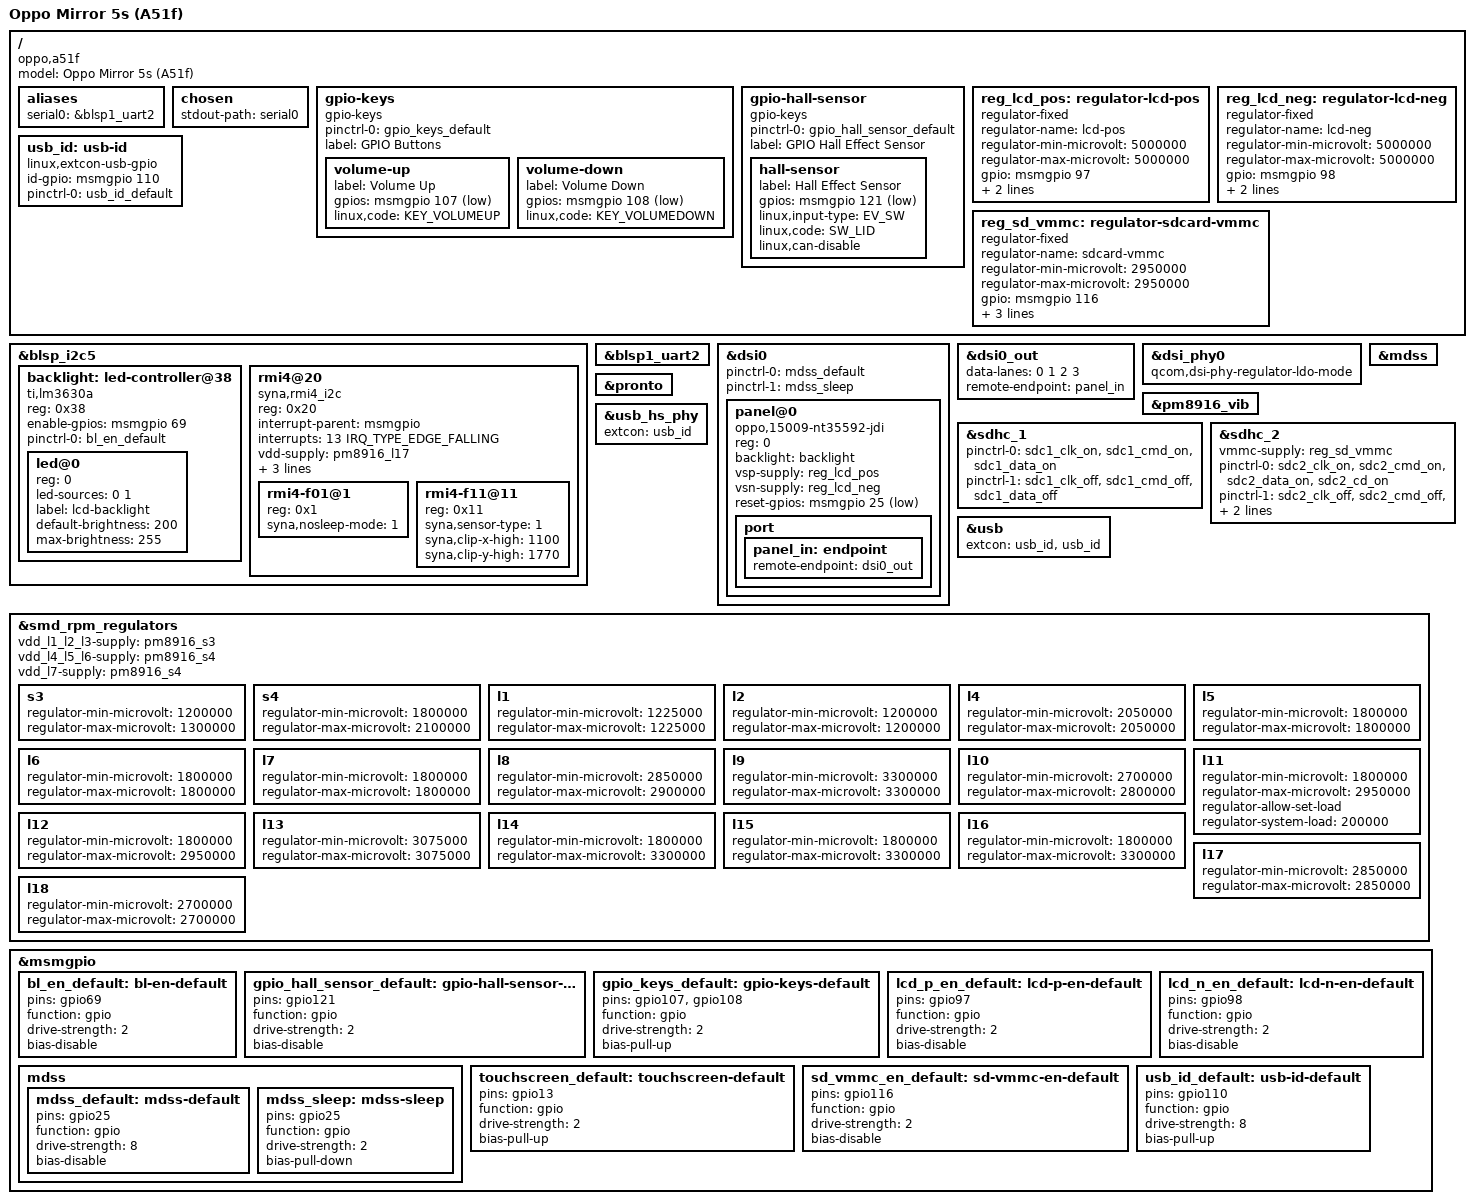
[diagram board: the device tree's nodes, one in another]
// SPDX-License-Identifier: GPL-2.0-only

/dts-v1/;

#include "msm8916-pm8916.dtsi"
#include "arm/qcom-msm8916-no-psci.dtsi"
#include <dt-bindings/gpio/gpio.h>

/ {
	model = "Oppo Mirror 5s (A51f)";
	compatible = "oppo,a51f", "qcom,msm8916";

	aliases {
		serial0 = &blsp1_uart2;
	};

	chosen {
		stdout-path = "serial0";
	};

	gpio-keys {
		compatible = "gpio-keys";

		pinctrl-names = "default";
		pinctrl-0 = <&gpio_keys_default>;

		label = "GPIO Buttons";

		volume-up {
			label = "Volume Up";
			gpios = <&msmgpio 107 GPIO_ACTIVE_LOW>;
			linux,code = <KEY_VOLUMEUP>;
		};

		volume-down {
			label = "Volume Down";
			gpios = <&msmgpio 108 GPIO_ACTIVE_LOW>;
			linux,code = <KEY_VOLUMEDOWN>;
		};
	};

	gpio-hall-sensor {
		compatible = "gpio-keys";

		pinctrl-names = "default";
		pinctrl-0 = <&gpio_hall_sensor_default>;

		label = "GPIO Hall Effect Sensor";

		hall-sensor {
			label = "Hall Effect Sensor";
			gpios = <&msmgpio 121 GPIO_ACTIVE_LOW>;
			linux,input-type = <EV_SW>;
			linux,code = <SW_LID>;
			linux,can-disable;
		};
	};

	reg_lcd_pos: regulator-lcd-pos {
		compatible = "regulator-fixed";
		regulator-name = "lcd-pos";
		regulator-min-microvolt = <5000000>;
		regulator-max-microvolt = <5000000>;
		gpio = <&msmgpio 97 GPIO_ACTIVE_HIGH>;
		enable-active-high;
		pinctrl-names = "default";
		pinctrl-0 = <&lcd_p_en_default>;
	};

	reg_lcd_neg: regulator-lcd-neg {
		compatible = "regulator-fixed";
		regulator-name = "lcd-neg";
		regulator-min-microvolt = <5000000>;
		regulator-max-microvolt = <5000000>;
		gpio = <&msmgpio 98 GPIO_ACTIVE_HIGH>;
		enable-active-high;
		pinctrl-names = "default";
		pinctrl-0 = <&lcd_n_en_default>;
	};

	reg_sd_vmmc: regulator-sdcard-vmmc {
		compatible = "regulator-fixed";
		regulator-name = "sdcard-vmmc";
		regulator-min-microvolt = <2950000>;
		regulator-max-microvolt = <2950000>;

		gpio = <&msmgpio 116 GPIO_ACTIVE_HIGH>;
		enable-active-high;

		startup-delay-us = <200>;

		pinctrl-names = "default";
		pinctrl-0 = <&sd_vmmc_en_default>;
	};

	usb_id: usb-id {
		compatible = "linux,extcon-usb-gpio";
		id-gpio = <&msmgpio 110 GPIO_ACTIVE_HIGH>;
		pinctrl-names = "default";
		pinctrl-0 = <&usb_id_default>;
	};
};

&blsp_i2c5 {
	status = "okay";

	backlight: led-controller@38 {
		compatible = "ti,lm3630a";
		reg = <0x38>;
		enable-gpios = <&msmgpio 69 GPIO_ACTIVE_HIGH>;
		pinctrl-names = "default";
		pinctrl-0 = <&bl_en_default>;
		#address-cells = <1>;
		#size-cells = <0>;

		led@0 {
			reg = <0>;
			led-sources = <0 1>;
			label = "lcd-backlight";
			default-brightness = <200>;
			max-brightness = <255>;
		};
	};

	rmi4@20 {
		compatible = "syna,rmi4_i2c";
		reg = <0x20>;
		#address-cells = <1>;
		#size-cells = <0>;

		interrupt-parent = <&msmgpio>;
		interrupts = <13 IRQ_TYPE_EDGE_FALLING>;

		vdd-supply = <&pm8916_l17>;
		vio-supply = <&pm8916_l6>;

		pinctrl-names = "default";
		pinctrl-0 = <&touchscreen_default>;

		syna,startup-delay-ms = <10>;

		rmi4-f01@1 {
			reg = <0x1>;
			syna,nosleep-mode = <1>; // Allow sleeping
		};

		rmi4-f11@11 {
			reg = <0x11>;
			syna,sensor-type = <1>; // Touchscreen
			syna,clip-x-high = <1100>;
			syna,clip-y-high = <1770>;
		};
	};
};

&blsp1_uart2 {
	status = "okay";
};

&dsi0 {
	pinctrl-names = "default", "sleep";
	pinctrl-0 = <&mdss_default>;
	pinctrl-1 = <&mdss_sleep>;

	panel@0 {
		compatible = "oppo,15009-nt35592-jdi";
		reg = <0>;

		backlight = <&backlight>;
		vsp-supply = <&reg_lcd_pos>;
		vsn-supply = <&reg_lcd_neg>;
		reset-gpios = <&msmgpio 25 GPIO_ACTIVE_LOW>;

		port {
			panel_in: endpoint {
				remote-endpoint = <&dsi0_out>;
			};
		};
	};
};

&dsi0_out {
	data-lanes = <0 1 2 3>;
	remote-endpoint = <&panel_in>;
};

&dsi_phy0 {
	qcom,dsi-phy-regulator-ldo-mode;
};

&mdss {
	status = "okay";
};

&pm8916_vib {
	status = "okay";
};

&pronto {
	status = "okay";
};

&sdhc_1 {
	status = "okay";

	pinctrl-names = "default", "sleep";
	pinctrl-0 = <&sdc1_clk_on &sdc1_cmd_on &sdc1_data_on>;
	pinctrl-1 = <&sdc1_clk_off &sdc1_cmd_off &sdc1_data_off>;
};

&sdhc_2 {
	status = "okay";
	vmmc-supply = <&reg_sd_vmmc>;

	pinctrl-names = "default", "sleep";
	pinctrl-0 = <&sdc2_clk_on &sdc2_cmd_on &sdc2_data_on &sdc2_cd_on>;
	pinctrl-1 = <&sdc2_clk_off &sdc2_cmd_off &sdc2_data_off &sdc2_cd_off>;

	cd-gpios = <&msmgpio 38 GPIO_ACTIVE_HIGH>;
};

&usb {
	status = "okay";
	extcon = <&usb_id>, <&usb_id>;
};

&usb_hs_phy {
	extcon = <&usb_id>;
};

&smd_rpm_regulators {
	vdd_l1_l2_l3-supply = <&pm8916_s3>;
	vdd_l4_l5_l6-supply = <&pm8916_s4>;
	vdd_l7-supply = <&pm8916_s4>;

	s3 {
		regulator-min-microvolt = <1200000>;
		regulator-max-microvolt = <1300000>;
	};

	s4 {
		regulator-min-microvolt = <1800000>;
		regulator-max-microvolt = <2100000>;
	};

	l1 {
		regulator-min-microvolt = <1225000>;
		regulator-max-microvolt = <1225000>;
	};

	l2 {
		regulator-min-microvolt = <1200000>;
		regulator-max-microvolt = <1200000>;
	};

	l4 {
		regulator-min-microvolt = <2050000>;
		regulator-max-microvolt = <2050000>;
	};

	l5 {
		regulator-min-microvolt = <1800000>;
		regulator-max-microvolt = <1800000>;
	};

	l6 {
		regulator-min-microvolt = <1800000>;
		regulator-max-microvolt = <1800000>;
	};

	l7 {
		regulator-min-microvolt = <1800000>;
		regulator-max-microvolt = <1800000>;
	};

	l8 {
		regulator-min-microvolt = <2850000>;
		regulator-max-microvolt = <2900000>;
	};

	l9 {
		regulator-min-microvolt = <3300000>;
		regulator-max-microvolt = <3300000>;
	};

	l10 {
		regulator-min-microvolt = <2700000>;
		regulator-max-microvolt = <2800000>;
	};

	l11 {
		regulator-min-microvolt = <1800000>;
		regulator-max-microvolt = <2950000>;
		regulator-allow-set-load;
		regulator-system-load = <200000>;
	};

	l12 {
		regulator-min-microvolt = <1800000>;
		regulator-max-microvolt = <2950000>;
	};

	l13 {
		regulator-min-microvolt = <3075000>;
		regulator-max-microvolt = <3075000>;
	};

	l14 {
		regulator-min-microvolt = <1800000>;
		regulator-max-microvolt = <3300000>;
	};

	l15 {
		regulator-min-microvolt = <1800000>;
		regulator-max-microvolt = <3300000>;
	};

	l16 {
		regulator-min-microvolt = <1800000>;
		regulator-max-microvolt = <3300000>;
	};

	l17 {
		regulator-min-microvolt = <2850000>;
		regulator-max-microvolt = <2850000>;
	};

	l18 {
		regulator-min-microvolt = <2700000>;
		regulator-max-microvolt = <2700000>;
	};
};

&msmgpio {
	bl_en_default: bl-en-default {
		pins = "gpio69";
		function = "gpio";

		drive-strength = <2>;
		bias-disable;
	};

	gpio_hall_sensor_default: gpio-hall-sensor-default {
		pins = "gpio121";
		function = "gpio";

		drive-strength = <2>;
		bias-disable;
	};

	gpio_keys_default: gpio-keys-default {
		pins = "gpio107", "gpio108";
		function = "gpio";

		drive-strength = <2>;
		bias-pull-up;
	};

	lcd_p_en_default: lcd-p-en-default {
		pins = "gpio97";
		function = "gpio";

		drive-strength = <2>;
		bias-disable;
	};

	lcd_n_en_default: lcd-n-en-default {
		pins = "gpio98";
		function = "gpio";

		drive-strength = <2>;
		bias-disable;
	};

	mdss {
		mdss_default: mdss-default {
			pins = "gpio25";
			function = "gpio";

			drive-strength = <8>;
			bias-disable;
		};
		mdss_sleep: mdss-sleep {
			pins = "gpio25";
			function = "gpio";

			drive-strength = <2>;
			bias-pull-down;
		};
	};

	touchscreen_default: touchscreen-default {
		pins = "gpio13";
		function = "gpio";

		drive-strength = <2>;
		bias-pull-up;
	};

	sd_vmmc_en_default: sd-vmmc-en-default {
		pins = "gpio116";
		function = "gpio";

		drive-strength = <2>;
		bias-disable;
	};

	usb_id_default: usb-id-default {
		pins = "gpio110";
		function = "gpio";

		drive-strength = <8>;
		bias-pull-up;
	};
};
